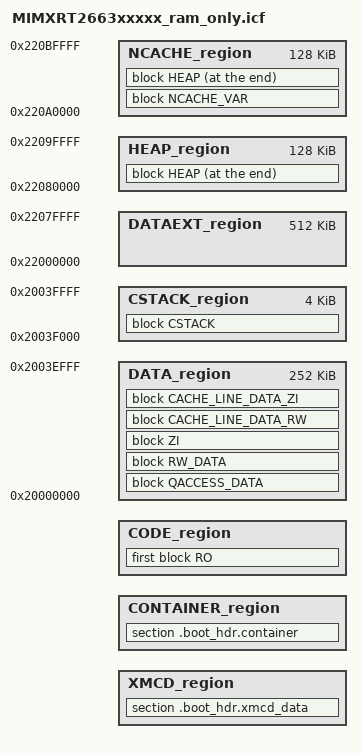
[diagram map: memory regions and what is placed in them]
/*
** ###################################################################
**     Processors:          MIMXRT2663AHP8A_cm85
**                          MIMXRT2663AVV8A_cm85
**                          MIMXRT2663CHPAA_cm85
**                          MIMXRT2663CVVAA_cm85
**                          MIMXRT2663DHPAA_cm85
**                          MIMXRT2663DVVAA_cm85
**                          MIMXRT2663XHP8A_cm85
**                          MIMXRT2663XHPAA_cm85
**                          MIMXRT2663XVV8A_cm85
**                          MIMXRT2663XVVAA_cm85
**
**     Compiler:            IAR ANSI C/C++ Compiler for ARM
**     Reference manual:    iMXRT2660RM Rev.1 DraftN, 08/2026
**     Version:             rev. 1.0, 2026-08-18
**     Build:               b260818
**
**     Abstract:
**         Linker file for the IAR ANSI C/C++ Compiler for ARM
**
**     Copyright 2016 Freescale Semiconductor, Inc.
**     Copyright 2016-2026 NXP
**     SPDX-License-Identifier: BSD-3-Clause
**
**     http:                 www.nxp.com
**     mail:                 support@nxp.com
**
** ###################################################################
*/

/* ========================== Hardware addresses ========================== */
/* ======================================================================== */
define symbol m_flash_start       = 0x60000000;
define symbol m_flash_size        = 0x04000000;
define symbol m_itcm_start        = 0x00000000;
define symbol m_itcm_size         = 0x00040000;
define symbol m_dtcm_start        = 0x20000000;
define symbol m_dtcm_size         = 0x00040000;
define symbol m_sram0_start       = 0x22000000;
define symbol m_sram0_size        = 0x00040000;
define symbol m_sram1_start       = 0x22040000;
define symbol m_sram1_size        = 0x00040000;
define symbol m_sram2_start       = 0x22080000;
define symbol m_sram2_size        = 0x00040000;
define symbol m_psram_start       = 0x88000000;
define symbol m_psram_size        = 0x02000000;

/* ========================== Offsets and sizes =========================== */
/* ======================================================================== */
define symbol m_usdhc_xmcd_offset    = 0x0;
define symbol m_usdhc_xmcd_size      = isdefinedsymbol(__usdhc_boot_header_enable__) ? 0x800  : 0;
define symbol m_usdhc_container_offset = 0x800;
define symbol m_usdhc_container_size = isdefinedsymbol(__usdhc_boot_header_enable__) ? 0x9000 : 0;
define symbol m_app_image_offset     = isdefinedsymbol(__usdhc_boot_header_enable__) ? 0xC000 : 0;
define symbol m_xmcd_offset          = m_usdhc_xmcd_offset;
define symbol m_xmcd_size            = m_usdhc_xmcd_size;
define symbol m_container_offset     = m_usdhc_container_offset;
define symbol m_container_size       = m_usdhc_container_size;
define symbol m_vector_table_size    = 0x600;
define symbol m_ncache_size          = 0x20000;

/* ====================== Region start/end addresses ====================== */
/* ======================================================================== */
if (isdefinedsymbol(__usdhc_boot_header_enable__)) {
  define symbol m_xmcd_start      = m_itcm_start + m_xmcd_offset;
  define symbol m_xmcd_end        = m_xmcd_start + m_xmcd_size - 1;
  define symbol m_container_start = m_itcm_start + m_container_offset;
  define symbol m_container_end   = m_container_start + m_container_size - 1;
}
define symbol m_ncache_start      = m_sram2_start + m_sram2_size - m_ncache_size;
define symbol m_ncache_end        = m_ncache_start + m_ncache_size - 1;
define symbol m_heap_start        = m_sram2_start;
define symbol m_heap_end          = m_ncache_start - 1;
define symbol m_dataext_start     = m_sram0_start;
define symbol m_dataext_end       = m_sram1_start + m_sram1_size - 1;

if (isdefinedsymbol(__stack_size__)) {
  define symbol __size_cstack__ = __stack_size__;
} else {
  define symbol __size_cstack__ = 0x1000;
}

if (isdefinedsymbol(__heap_size__)) {
  define symbol __size_heap__ = __heap_size__;
} else {
  define symbol __size_heap__ = 0x1000;
}

define symbol m_cstack_start      = m_dtcm_start + m_dtcm_size - __size_cstack__;
define symbol m_cstack_end        = m_dtcm_start + m_dtcm_size - 1;

/* ================ Target specific CODE / DATA addresses ================= */
/* ======================================================================== */
define symbol m_code_start        = m_itcm_start + m_app_image_offset;
define symbol m_code_end          = m_itcm_start + m_itcm_size - 1;
define symbol m_data_start        = m_dtcm_start;
define symbol m_data_end          = m_dtcm_start + m_dtcm_size - __size_cstack__ - 1;

/* ============================ Memory regions ============================ */
/* ======================================================================== */
define memory mem with size = 4G;
if (isdefinedsymbol(__usdhc_boot_header_enable__)) {
  define region XMCD_region      = mem:[from m_xmcd_start      to m_xmcd_end];
  define region CONTAINER_region = mem:[from m_container_start to m_container_end];
}
define region CODE_region      = mem:[from m_code_start      to m_code_end];
define region DATA_region      = mem:[from m_data_start      to m_data_end];
define region CSTACK_region    = mem:[from m_cstack_start    to m_cstack_end];
define region NCACHE_region    = mem:[from m_ncache_start    to m_ncache_end];
define region HEAP_region      = mem:[from m_heap_start      to m_heap_end];
define region DATAEXT_region   = mem:[from m_dataext_start   to m_dataext_end];

/* ========================== Block definitions =========================== */
/* ======================================================================== */
/* end alignment = 512: for eMMC boot with ITCM as destination, the container
 * image size (__section_size("RO")) must be a multiple of 512 bytes (one
 * eMMC sector).  end alignment pads the RO block to the next sector boundary. */
define block RO                  with fixed order, end alignment = 512 { readonly section .intvec, readonly, section CodeQuickAccess, section .textrw };
define block RW_DATA             { rw data };
define block ZI                  { zi };
define block QACCESS_DATA        { section DataQuickAccess };
define block NCACHE_VAR          { section NonCacheable, section NonCacheable.init };
define block CACHE_LINE_DATA_RW  with alignment = 32, end alignment = 32 { section CacheLineData.init };
define block CACHE_LINE_DATA_ZI  with alignment = 32, end alignment = 32 { section CacheLineData };
define block CSTACK              with alignment = 8, size = __size_cstack__ { };
define block HEAP                with alignment = 8, size = __size_heap__   { };

/* ====================== Initialization directives ======================= */
/* ======================================================================== */
initialize by copy { readwrite };
do not initialize   { section .noinit };

if (isdefinedsymbol(__usdhc_boot_header_enable__)) {
  keep { section .boot_hdr.xmcd_data, section .boot_hdr.container };
}

/* ========================= Placement directives ========================= */
/* ======================================================================== */
if (isdefinedsymbol(__usdhc_boot_header_enable__)) {
  place in XMCD_region      { section .boot_hdr.xmcd_data };
  place in CONTAINER_region { section .boot_hdr.container };
}

place in CODE_region      { first block RO };

place in DATA_region      { block QACCESS_DATA };
place in DATA_region      { block RW_DATA };
place in DATA_region      { block ZI };
place in DATA_region      { block CACHE_LINE_DATA_RW, block CACHE_LINE_DATA_ZI };

place in CSTACK_region    { block CSTACK };
place in NCACHE_region    { block NCACHE_VAR };
place in DATAEXT_region   { };

if (isdefinedsymbol(__heap_noncacheable__)) {
  place at end of NCACHE_region { block HEAP };
} else {
  place at end of HEAP_region   { block HEAP };
}

/* =========================== Exported symbols =========================== */
/* ======================================================================== */
define exported symbol __VECTOR_TABLE             = m_code_start;
define exported symbol __NCACHE_REGION_START      = m_ncache_start;
define exported symbol __NCACHE_REGION_SIZE       = m_ncache_end - m_ncache_start + 1;
if (isdefinedsymbol(__usdhc_boot_header_enable__)) {
  define exported symbol __CONTAINER_IMG_OFFSET   = m_app_image_offset - m_container_offset;
  define exported symbol __CONTAINER_IMG_LOAD_ADDR  = m_code_start;
  define exported symbol __CONTAINER_IMG_ENTRY_ADDR = m_code_start;
}
